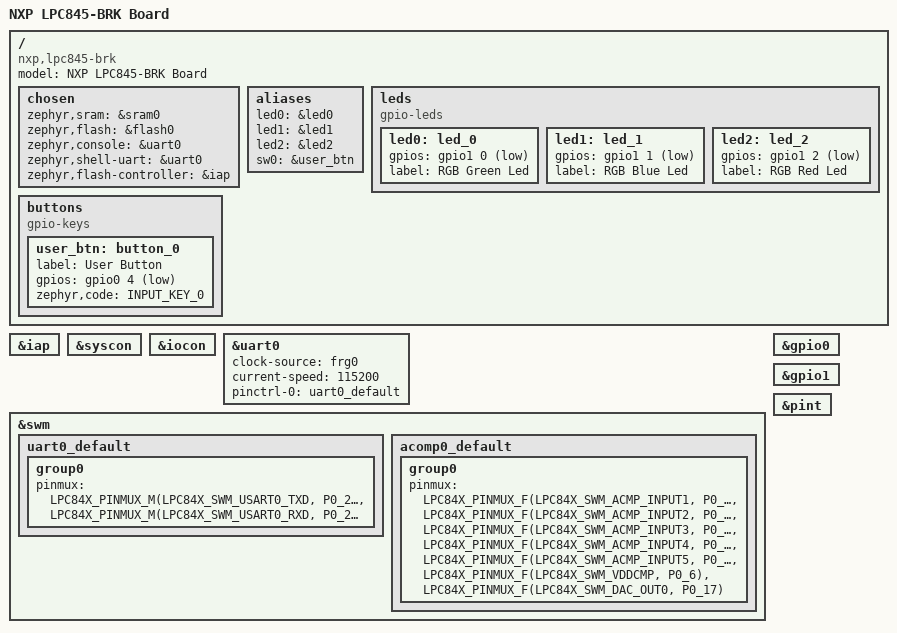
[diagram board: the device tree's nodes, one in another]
/*
 * Copyright (c) 2026 Aerlync Labs Inc.
 *
 * SPDX-License-Identifier: Apache-2.0
 */

/dts-v1/;

#include <nxp/lpc/nxp_lpc845.dtsi>
#include <zephyr/dt-bindings/pinctrl/lpc84x-pinctrl.h>
#include <zephyr/dt-bindings/gpio/gpio.h>
#include <zephyr/dt-bindings/input/input-event-codes.h>

/ {
	model = "NXP LPC845-BRK Board";
	compatible = "nxp,lpc845-brk";

	chosen {
		zephyr,sram = &sram0;
		zephyr,flash = &flash0;
		zephyr,console = &uart0;
		zephyr,shell-uart = &uart0;
		zephyr,flash-controller = &iap;
	};

	aliases {
		led0 = &led0;
		led1 = &led1;
		led2 = &led2;
		sw0 = &user_btn;
	};

	leds {
		compatible = "gpio-leds";

		led0: led_0 {
			gpios = <&gpio1 0 GPIO_ACTIVE_LOW>;
			label = "RGB Green Led";
		};

		led1: led_1 {
			gpios = <&gpio1 1 GPIO_ACTIVE_LOW>;
			label = "RGB Blue Led";
		};

		led2: led_2 {
			gpios = <&gpio1 2 GPIO_ACTIVE_LOW>;
			label = "RGB Red Led";
		};
	};

	buttons {
		compatible = "gpio-keys";

		user_btn: button_0 {
			label = "User Button";
			gpios = <&gpio0 4 (GPIO_PULL_UP | GPIO_ACTIVE_LOW)>;
			zephyr,code = <INPUT_KEY_0>;
		};
	};
};

&iap {
	status = "okay";
};

&syscon {
	status = "okay";
};

&iocon {
	status = "okay";
};

&uart0 {
	status = "okay";
	clock-source = "frg0";
	current-speed = <115200>;
	pinctrl-0 = <&uart0_default>;
	pinctrl-names = "default";
};

&swm {
	status = "okay";

	uart0_default: uart0_default {
		group0 {
			pinmux = <LPC84X_PINMUX_M(LPC84X_SWM_USART0_TXD, P0_25)>,
				 <LPC84X_PINMUX_M(LPC84X_SWM_USART0_RXD, P0_24)>;
		};
	};

	acomp0_default: acomp0_default {
		group0 {
			pinmux = <LPC84X_PINMUX_F(LPC84X_SWM_ACMP_INPUT1, P0_0)>,
				 <LPC84X_PINMUX_F(LPC84X_SWM_ACMP_INPUT2, P0_1)>,
				 <LPC84X_PINMUX_F(LPC84X_SWM_ACMP_INPUT3, P0_14)>,
				 <LPC84X_PINMUX_F(LPC84X_SWM_ACMP_INPUT4, P0_23)>,
				 <LPC84X_PINMUX_F(LPC84X_SWM_ACMP_INPUT5, P0_30)>,
				 <LPC84X_PINMUX_F(LPC84X_SWM_VDDCMP, P0_6)>,
				 <LPC84X_PINMUX_F(LPC84X_SWM_DAC_OUT0, P0_17)>;
		};
	};
};

&gpio0 {
	status = "okay";
};

&gpio1 {
	status = "okay";
};

&pint {
	status = "okay";
};
